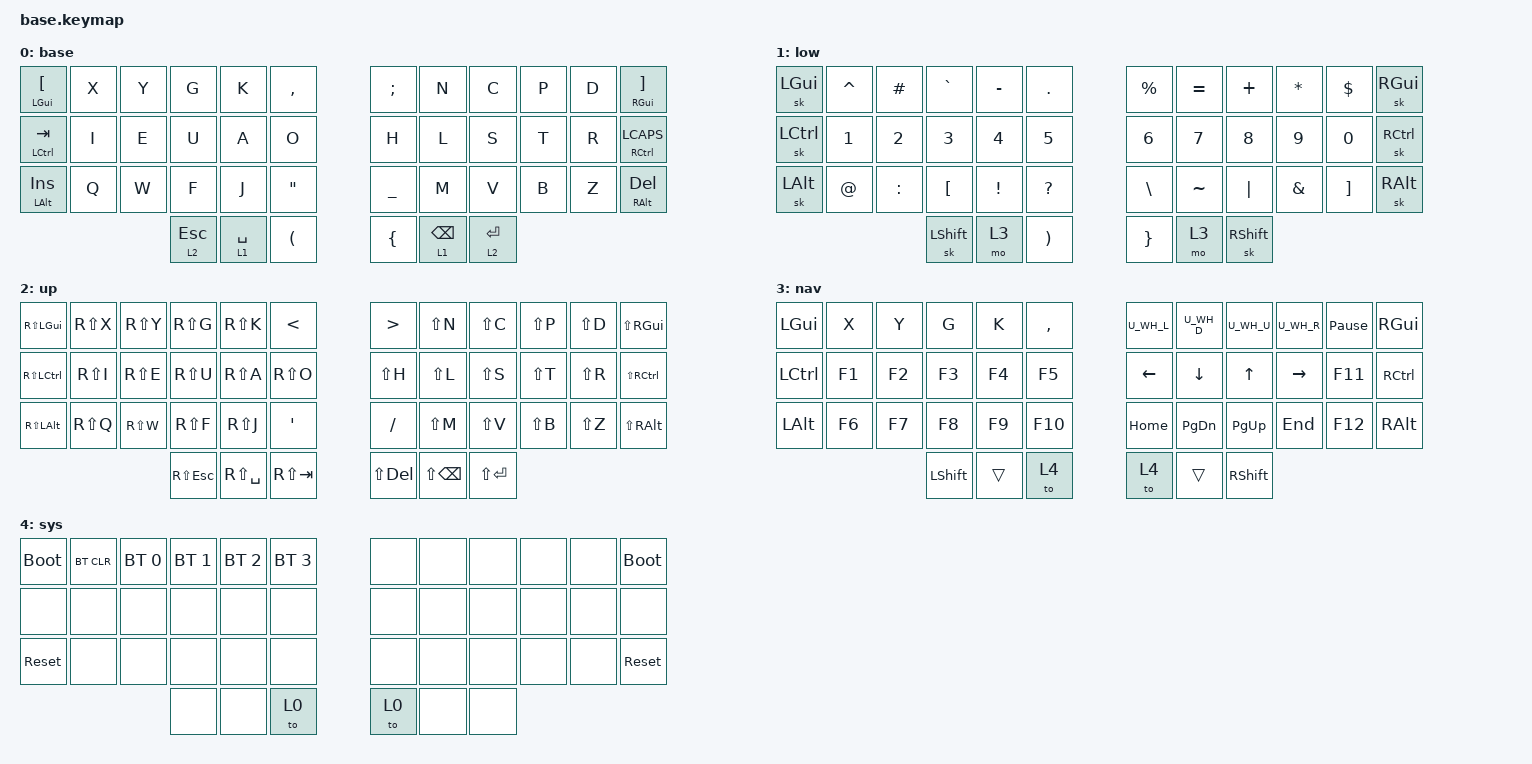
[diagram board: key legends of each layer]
#include <behaviors.dtsi>
#include <dt-bindings/zmk/keys.h>
#if CONFIG_WIRELESS
    #include <dt-bindings/zmk/bt.h>
    #define _BT_SEL_KEYS_ &bt BT_SEL 0 &bt BT_SEL 1 &bt BT_SEL 2 &bt BT_SEL 3 &bt BT_CLR
#else
    #define _BT_SEL_KEYS_ &trans &trans &trans &trans &trans
#endif

#include "../zmk-nodefree-config/helper.h"
#include "../zmk-nodefree-config/international_chars/greek.dtsi"
#include "../zmk-nodefree-config/international_chars/german.dtsi"

#define DEF 0
#define NAV 1
#define FN 2
#define NUM 3
#define SYS 4
#define UC 5
#define MOUSE 6

#include "combos.dtsi"  // requires layer aliases
#include "mouse.dtsi"
#include "extra_keys.h"

#define XXX &none
#define ___ &trans

/* Global settings */

#define QUICK_TAP_MS 175

&sk {  // sticky-key config
    release-after-ms = <600>;  // release after 0.6s
    quick-release;             // no double capitalization when rolling keys
};

&sl {  // sticky-layer config
    ignore-modifiers;          // allow chording sticky mods & layers
};

&lt {  // layer-tap config
    flavor = "balanced";
    tapping-term-ms = <200>;
    quick-tap-ms = <QUICK_TAP_MS>;
};

/* Homerow mods */

#define KEYS_L LT0 LT1 LT2 LT3 LT4 LM0 LM1 LM2 LM3 LM4 LB0 LB1 LB2 LB3 LB4  // left hand
#define KEYS_R RT0 RT1 RT2 RT3 RT4 RM0 RM1 RM2 RM3 RM4 RB0 RB1 RB2 RB3 RB4  // right hand
#define THUMBS LH2 LH1 LH0 RH0 RH1 RH2                                      // thumbs

#define MAKE_HRM(NAME, HOLD, TAP, TRIGGER_POS) \
    ZMK_BEHAVIOR(NAME, hold_tap, \
        flavor = "balanced"; \
        tapping-term-ms = <280>; \
        quick-tap-ms = <QUICK_TAP_MS>; \
        global-quick-tap-ms = <150>; \
        bindings = <HOLD>, <TAP>; \
        hold-trigger-key-positions = <TRIGGER_POS>; \
        hold-trigger-on-release; \
    )
MAKE_HRM(hml, &kp, &kp, KEYS_R THUMBS)  // left-hand HRMs
MAKE_HRM(hmr, &kp, &kp, KEYS_L THUMBS)  // right-hand HRMs

MAKE_HRM(hml_repeat, &kp, &key_repeat, KEYS_R THUMBS)  // used for HRM-combo
MAKE_HRM(hmr_lpar_lt, &kp, &lpar_lt, KEYS_L THUMBS)    // "    "   "   "
MAKE_HRM(hmr_rpar_gt, &kp, &rpar_gt, KEYS_L THUMBS)    // "    "   "   "

MAKE_HRM(hml_repeat, &kp, &key_repeat, KEYS_R THUMBS)  // used for HRM-combo
MAKE_HRM(hmr_lpar_lt, &kp, &lpar_lt, KEYS_L THUMBS)    // "    "   "   "
MAKE_HRM(hmr_rpar_gt, &kp, &rpar_gt, KEYS_L THUMBS)    // "    "   "   "

/* Nav cluster */

// long-tap action on hold, short-tap action on all interrupts
#define MT_CORE \
    flavor = "tap-preferred"; \
    tapping-term-ms = <200>; \
    quick-tap-ms = <200>; \
    hold-trigger-key-positions = <0>;

&mt { MT_CORE };
ZMK_BEHAVIOR(mt_home, hold_tap, bindings = <&masked_home>, <&kp>; MT_CORE)
ZMK_BEHAVIOR(mt_end,  hold_tap,  bindings = <&masked_end>, <&kp>; MT_CORE)

#define NAV_LEFT  &mt_home 0   LEFT    // tap: left  | long-tap: beginning of line
#define NAV_RIGHT &mt_end 0    RIGHT   // tap: right | long-tap: end       of line
#define NAV_UP    &mt LC(HOME) UP      // tap: up    | long-tap: beginning of document
#define NAV_DOWN  &mt LC(END)  DOWN    // tap: down  | long-tap: end       of document
#define NAV_BSPC  &mt LC(BSPC) BSPC    // tap: bspc  | long-tap: delete word backward
#define NAV_DEL   &mt LC(DEL)  DEL     // tap: del   | long-tap: delete word forward

// mask CTRL when holding left/right to avoid accidental jumps to beginning/end of document
#define MASK_MODS(NAME, MODS, BINDING) \
    ZMK_BEHAVIOR(NAME, mod_morph, \
        bindings = <BINDING>, <BINDING>; \
        mods = <MODS>; \
    )
MASK_MODS(masked_home, (MOD_LCTL), &kp HOME)
MASK_MODS(masked_end,  (MOD_LCTL), &kp END)

/* Caps-word, num-word and smart-mouse */

// tap: sticky-shift | shift + tap/ double-tap: caps-word | hold: shift
ZMK_BEHAVIOR(smart_shft, mod_morph,
    bindings = <&sk LSHFT>, <&caps_word>;
    mods = <(MOD_LSFT)>;
)
&caps_word {  // mods deactivate caps-word, requires PR #1441
    /delete-property/ ignore-modifiers;
};

// tap: num-word | double-tap: sticky num-layer | hold: num-layer
#define SMART_NUM &smart_num NUM 0
ZMK_BEHAVIOR(smart_num, hold_tap,
    flavor = "balanced";
    tapping-term-ms = <200>;
    quick-tap-ms = <QUICK_TAP_MS>;
    bindings = <&mo>, <&num_dance>;
)
ZMK_BEHAVIOR(num_dance, tap_dance,
    tapping-term-ms = <200>;
    bindings = <&num_word>, <&sl NUM>;  // reverse this for sticky-num on single tap
)
&num_word {  // num-word, requires PR #1441
    layers = <NUM>;
};

// smart-mouse, requires PR #1366
ZMK_BEHAVIOR(smart_mouse, tri_state,
    bindings = <&tog MOUSE>, <&none>, <&tog MOUSE>;
    ignored-key-positions = <LT1 LT3 RT1 RT2 RT3 RM1 RM2 RM3 RH0 RH1>;
    ignored-layers = <MOUSE>;
)

/* Custom behaviors */

// Alt+Tab swapper, requires PR #1366
ZMK_BEHAVIOR(swapper, tri_state,
    bindings = <&kt LGUI>, <&kp TAB>, <&kt LGUI>;
    ignored-key-positions = <LT2>;
)

// Sticky layer + sticky shift (workaround for issue #1421)
ZMK_BEHAVIOR(sls, sticky_key,
    release-after-ms = <1000>;
    bindings = <&uc_shift>;
    ignore-modifiers;
)
ZMK_BEHAVIOR(uc_shift, macro,
    wait-ms = <0>;
    tap-ms = <1>;
    bindings = <&macro_press &mo UC &kp LSHFT>
             , <&macro_pause_for_release>
             , <&macro_release &mo UC &kp LSHFT>;
)

// tap: space | shift + tap: dot -> space -> sticky shift | hold: activate layer
ZMK_BEHAVIOR(lt_spc, hold_tap,
    flavor = "balanced";
    tapping-term-ms = <200>;
    quick-tap-ms = <QUICK_TAP_MS>;
    bindings = <&mo>, <&spc_morph>;
)
ZMK_BEHAVIOR(spc_morph, mod_morph,
    bindings = <&kp SPACE>, <&dot_spc>;
    mods = <(MOD_LSFT|MOD_RSFT)>;
)
ZMK_BEHAVIOR(dot_spc, macro,
    wait-ms = <0>;
    tap-ms = <5>;
    bindings = <&kp DOT &kp SPACE &sk LSHFT>;
)

// tap: backspace | lshft + tap: delete | rshft + tap: shift-delete
ZMK_BEHAVIOR(bs_del, mod_morph,
    bindings = <&kp BSPC>, <&kp DEL>;
    mods = <(MOD_LSFT|MOD_RSFT)>;
    keep-mods = <MOD_RSFT>;
)

// tap: left-parenthesis | shft + tap: less-than
ZMK_BEHAVIOR(lpar_lt, mod_morph,
    bindings = <&kp LPAR>, <&kp LT>;
    mods = <(MOD_LSFT|MOD_RSFT)>;
)

// tap: right-parenthesis | shft + tap: greater-than
ZMK_BEHAVIOR(rpar_gt, mod_morph,
    bindings = <&kp RPAR>, <&kp GT>;
    mods = <(MOD_LSFT|MOD_RSFT)>;
)

ZMK_BEHAVIOR(comma_dance, tap_dance,
    tapping-term-ms = <200>;
    bindings = <&mt SEMI COMMA>, <&kp BSLH>;
)
ZMK_BEHAVIOR(dot_dance, tap_dance,
    tapping-term-ms = <200>;
    bindings = <&mt COLON DOT>, <&kp EXCL>;
)
ZMK_BEHAVIOR(qt_dance, tap_dance,
    tapping-term-ms = <200>;
    bindings = <&mt DQT QMARK>, <&kp SQT>;
)
ZMK_BEHAVIOR(hyper_dance, tap_dance,
    tapping-term-ms = <200>;
    bindings = <&mt RS(RC(RA(RGUI))) RS(RC(RA(H)))>, <&kp RS(RC(RA(J)))>;
)

ZMK_BEHAVIOR(nayeon, macro,
    wait-ms = <0>;
    tap-ms = <5>;
    bindings = <&kp N &kp A &kp Y &kp E &kp O &kp N &kp RET>;
)

// Windows sleep key
ZMK_BEHAVIOR(win_sleep, macro,
    wait-ms = <100>;
    tap-ms = <5>;
    bindings = <&kp LG(X) &kp U &kp S>;
)

// misc aliases
#define CANCEL      &kp K_CANCEL             // cancel caps-word, num-word and smart-mouse
#define DSK_PREV    &hmr RSHFT LG(LC(LEFT))  // previous desktop
#define DSK_NEXT    &hmr LALT LG(LC(RIGHT))  // next B    desktop
#define VOL_DOWN    &hmr LCTRL C_VOL_DN

/* Keymap */

//ZMK_CONDITIONAL_LAYER(NAV FN, SYS)  // FN + NAV --> SYS

ZMK_LAYER(base,
//╭───────────────╮ ╭──────────────┬──────────────┬──────────────┬──────────────┬──────────────╮ ╭──────╮ ╭──────────────┬──────────────┬──────────────┬──────────────┬─────────────╮ ╭───────────────╮
   &mt LGUI LBKT     &kp X          &kp Y          &kp G          &kp K          &kp COMMA                 &kp SEMI       &kp N          &kp C          &kp P          &kp D           &mt RGUI RBKT  
//├───────────────┤ ├──────────────┼──────────────┼──────────────┼──────────────┼──────────────┤ ├──────┤ ├──────────────┼──────────────┼──────────────┼──────────────┼─────────────┤ ├───────────────┤
   &mt LCTRL TAB     &kp I          &kp E          &kp U          &kp A          &kp O                     &kp H          &kp L          &kp S          &kp T          &kp R           &mt RCTRL LCAPS
//├───────────────┤ ├──────────────┼──────────────┼──────────────┼──────────────┼──────────────┤ ├──────┤ ├──────────────┼──────────────┼──────────────┼──────────────┼─────────────┤ ├───────────────┤
   &mt LALT INS      &kp Q          &kp W          &kp F          &kp J          &kp DQT                   &kp UNDERSCORE &kp M          &kp V          &kp B          &kp Z           &mt RALT DEL   
//├───────────────┤ ╰──────────────┼──────────────┴──────────────┼──────────────┼──────────────┤ ├──────┤ ├──────────────┼──────────────┼──────────────┴──────────────┼─────────────╯ ├───────────────┤
                                                //    &kp ESC        &kp SPACE      &kp LPAR                  &kp LBRC       &kp BSPC       &kp ENTER
                                                   &lt 2 ESC      &lt 1 SPACE    &kp LPAR                  &kp LBRC       &lt 1 BSPC     &lt 2 ENTER
//                                                ╰──────────────┼──────────────┴──────────────╯ ╰──────╯ ╰──────────────┴──────────────┼──────────────╯
)

ZMK_LAYER(low,
//╭───────────────╮ ╭──────────────┬──────────────┬──────────────┬──────────────┬──────────────╮ ╭──────╮ ╭──────────────┬──────────────┬──────────────┬──────────────┬─────────────╮ ╭───────────────╮
   &sk LGUI          &kp CARET      &kp HASH       &kp GRAVE      &kp MINUS      &kp PERIOD                &kp PRCNT      &kp EQUAL      &kp PLUS       &kp STAR       &kp DOLLAR      &sk RGUI
//├───────────────┤ ├──────────────┼──────────────┼──────────────┼──────────────┼──────────────┤ ├──────┤ ├──────────────┼──────────────┼──────────────┼──────────────┼─────────────┤ ├───────────────┤
   &sk LCTRL         &kp N1         &kp N2         &kp N3         &kp N4         &kp N5                    &kp N6         &kp N7         &kp N8         &kp N9         &kp N0          &sk RCTRL
//├───────────────┤ ├──────────────┼──────────────┼──────────────┼──────────────┼──────────────┤ ├──────┤ ├──────────────┼──────────────┼──────────────┼──────────────┼─────────────┤ ├───────────────┤
   &sk LALT          &kp AT         &kp COLON      &kp LBKT       &kp EXCL       &kp QMARK                 &kp BSLH       &kp TILDE      &kp PIPE       &kp AMPS       &kp RBKT        &sk RALT
//├───────────────┤ ╰──────────────┼──────────────┴──────────────┼──────────────┼──────────────┤ ├──────┤ ├──────────────┼──────────────┼──────────────┴──────────────┼─────────────╯ ├───────────────┤
                                                //    &sk LSHIFT     &kp J          &kp RPAR                  &kp RBRC       &kp J          &sk RSHIFT
                                                   &sk LSHIFT     &mo 3          &kp RPAR                  &kp RBRC       &mo 3          &sk RSHIFT
//                                                ╰──────────────┼──────────────┴──────────────╯ ╰──────╯ ╰──────────────┴──────────────┼──────────────╯
)

ZMK_LAYER(up,
//╭───────────────╮ ╭──────────────┬──────────────┬──────────────┬──────────────┬──────────────╮ ╭──────╮ ╭──────────────┬──────────────┬──────────────┬──────────────┬─────────────╮ ╭───────────────╮
   &kp RS(LGUI)      &kp RS(X)      &kp RS(Y)      &kp RS(G)      &kp RS(K)      &kp LT                    &kp GT         &kp LS(N)      &kp LS(C)      &kp LS(P)      &kp LS(D)       &kp LS(RGUI)  
//├───────────────┤ ├──────────────┼──────────────┼──────────────┼──────────────┼──────────────┤ ├──────┤ ├──────────────┼──────────────┼──────────────┼──────────────┼─────────────┤ ├───────────────┤
   &kp RS(LCTRL)     &kp RS(I)      &kp RS(E)      &kp RS(U)      &kp RS(A)      &kp RS(O)                 &kp LS(H)      &kp LS(L)      &kp LS(S)      &kp LS(T)      &kp LS(R)       &kp LS(RCTRL)    
//├───────────────┤ ├──────────────┼──────────────┼──────────────┼──────────────┼──────────────┤ ├──────┤ ├──────────────┼──────────────┼──────────────┼──────────────┼─────────────┤ ├───────────────┤
   &kp RS(LALT)      &kp RS(Q)      &kp RS(W)      &kp RS(F)      &kp RS(J)      &kp SQT                   &kp FSLH       &kp LS(M)      &kp LS(V)      &kp LS(B)      &kp LS(Z)       &kp LS(RALT)   
//├───────────────┤ ╰──────────────┼──────────────┴──────────────┼──────────────┼──────────────┤ ├──────┤ ├──────────────┼──────────────┼──────────────┴──────────────┼─────────────╯ ├───────────────┤
                                                   &kp RS(ESC)    &kp RS(SPACE)  &kp RS(TAB)               &kp LS(DEL)    &kp LS(BSPC)   &kp LS(ENTER)
//                                                ╰──────────────┼──────────────┴──────────────╯ ╰──────╯ ╰──────────────┴──────────────┼──────────────╯
)

ZMK_LAYER(nav,
//╭───────────────╮ ╭──────────────┬──────────────┬──────────────┬──────────────┬──────────────╮ ╭──────╮ ╭──────────────┬──────────────┬──────────────┬──────────────┬─────────────╮ ╭───────────────╮
   &kp LGUI          &kp X          &kp Y          &kp G          &kp K          &kp COMMA                 U_WH_L         U_WH_D         U_WH_U         U_WH_R         &kp PAUSE_BREAK &kp RGUI
//├───────────────┤ ├──────────────┼──────────────┼──────────────┼──────────────┼──────────────┤ ├──────┤ ├──────────────┼──────────────┼──────────────┼──────────────┼─────────────┤ ├───────────────┤
   &kp LCTRL         &kp F1         &kp F2         &kp F3         &kp F4         &kp F5                    &kp LEFT       &kp DOWN       &kp UP         &kp RIGHT      &kp F11         &kp RCTRL
//├───────────────┤ ├──────────────┼──────────────┼──────────────┼──────────────┼──────────────┤ ├──────┤ ├──────────────┼──────────────┼──────────────┼──────────────┼─────────────┤ ├───────────────┤
   &kp LALT          &kp F6         &kp F7         &kp F8         &kp F9         &kp F10                   &kp HOME       &kp PG_DN      &kp PG_UP      &kp END        &kp F12         &kp RALT
//├───────────────┤ ╰──────────────┼──────────────┴──────────────┼──────────────┼──────────────┤ ├──────┤ ├──────────────┼──────────────┼──────────────┴──────────────┼─────────────╯ ├───────────────┤
                                                   &kp LSHIFT     &trans         &to 4                     &to 4          &trans         &kp RSHIFT
//                                                ╰──────────────┼──────────────┴──────────────╯ ╰──────╯ ╰──────────────┴──────────────┼──────────────╯
)

ZMK_LAYER(sys,
//╭───────────────╮ ╭──────────────┬──────────────┬──────────────┬──────────────┬──────────────╮ ╭──────╮ ╭──────────────┬──────────────┬──────────────┬──────────────┬─────────────╮ ╭───────────────╮
   &bootloader       &bt BT_CLR     &bt BT_SEL 0   &bt BT_SEL 1   &bt BT_SEL 2   &bt BT_SEL 3              &none          &none          &none          &none          &none           &bootloader
//├───────────────┤ ├──────────────┼──────────────┼──────────────┼──────────────┼──────────────┤ ├──────┤ ├──────────────┼──────────────┼──────────────┼──────────────┼─────────────┤ ├───────────────┤
   &none             &none          &none          &none          &none          &none                     &none          &none          &none          &none          &none           &none            
//├───────────────┤ ├──────────────┼──────────────┼──────────────┼──────────────┼──────────────┤ ├──────┤ ├──────────────┼──────────────┼──────────────┼──────────────┼─────────────┤ ├───────────────┤
   &sys_reset        &none          &none          &none          &none          &none                     &none          &none          &none          &none          &none           &sys_reset
//├───────────────┤ ╰──────────────┼──────────────┴──────────────┼──────────────┼──────────────┤ ├──────┤ ├──────────────┼──────────────┼──────────────┴──────────────┼─────────────╯ ├───────────────┤
                                                   &none          &none          &to 0                     &to 0          &none          &none          
                                            //    ╰──────────────┼──────────────┴──────────────╯ ╰──────╯ ╰──────────────┴──────────────┼──────────────╯
)

// ZMK_LAYER(uc,
// //╭───────────────╮ ╭─────────────┬─────────────┬─────────────┬─────────────┬─────────────╮ ╭──────╮ ╭─────────────┬─────────────┬─────────────┬─────────────┬─────────────╮ ╭──────╮
//     X_LT     ___           &el_omega     &el_phi       &el_pi        &el_beta                 ___           &el_lambda    &el_upsilon   &el_psi       &de_eszett      X_RT
// //├───────────────┤ ├─────────────┼─────────────┼─────────────┼─────────────┼─────────────┤ ├──────┤ ├─────────────┼─────────────┼─────────────┼─────────────┼─────────────┤ ├──────┤
//     X_LM     &el_alpha     &el_rho       &el_sigma     &el_tau       &el_gamma                &el_mu        &el_nu        &el_epsilon   &el_iota      &el_omikron     X_RM
// //├───────────────┤ ├─────────────┼─────────────┼─────────────┼─────────────┼─────────────┤ ├──────┤ ├─────────────┼─────────────┼─────────────┼─────────────┼─────────────┤ ├──────┤
//     X_LB     &el_zeta      &el_xi        &el_chi       &el_delta     &el_theta                &el_kappa     &el_eta       &de_ae        &de_oe        &de_ue          X_RB
// //├───────────────┤ ╰─────────────┼─────────────┴─────────────┼─────────────┼─────────────┤ ├──────┤ ├─────────────┼─────────────┼─────────────┴───────────────────────────╯ ├──────┤
//     ___                                                ___           ___                      ___           ___                                                       ___
// //╰───────────────╯                                           ╰─────────────┴─────────────╯ ╰──────╯ ╰───────────────────────────╯                                           ╰──────╯
// )

// ZMK_LAYER(mouse,
// //╭───────────────╮ ╭─────────────┬─────────────┬─────────────┬─────────────┬─────────────╮ ╭──────╮ ╭─────────────┬─────────────┬─────────────┬─────────────┬─────────────╮ ╭──────╮
//     X_LT     ___           ___           ___           ___           ___                      ___           U_WH_D        U_MS_U         U_WH_U       ___             X_RT
// //├───────────────┤ ├─────────────┼─────────────┼─────────────┼─────────────┼─────────────┤ ├──────┤ ├─────────────┼─────────────┼─────────────┼─────────────┼─────────────┤ ├──────┤
//     X_LM     ___           ___           ___           ___           ___                      ___           U_MS_L        U_MS_D         U_MS_R       ___             X_RM
// //├───────────────┤ ├─────────────┼─────────────┼─────────────┼─────────────┼─────────────┤ ├──────┤ ├─────────────┼─────────────┼─────────────┼─────────────┼─────────────┤ ├──────┤
//     X_LB     ___           ___           ___           ___           ___                      ___           ___           ___            ___          ___             X_RB
// //├───────────────┤ ╰─────────────┼─────────────┴─────────────┼─────────────┼─────────────┤ ├──────┤ ├─────────────┼─────────────┼─────────────┴───────────────────────────╯ ├──────┤
//     ___                                                ___           ___                      U_BTN2        U_BTN1                                                    ___
// //╰───────────────╯                                           ╰─────────────┴─────────────╯ ╰──────╯ ╰─────────────┴─────────────╯                                           ╰──────╯
// )

/* vim: set ft=c tw=174: */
